# STM32F412Zx register map
File version: 1.0
Registers are 32-bit, read-write, reset 0x0 unless marked. A register's access mark holds for its fields unless they carry their own. Offsets are from the block's base; [hi:lo] are bit positions; {n}, {i} and the like mark numbered series; 'fields as' and 'values as' point back to an identical list.

## SYSCFG — System configuration controller
Base 0x40013800
0x00 MEMRMP — SYSCFG memory remap register
  [1:0] MEM_MODE — SYSCFG_Memory Remap Config
    0=FLASH (Main Flash memory mapped at 0x00000000); 1=SYSTEMFLASH (System Flash memory mapped at 0x00000000); 3=SRAM (SRAM1 mapped at 0x00000000); 2=FSMC (FSMC(NOR/PSRAM 1 and 2) mapped at 0x00000000)
0x04 PMC — SYSCFG peripheral mode configuration register
  [16] ADC1DC2 — Refer to AN4073 on how to use this bit
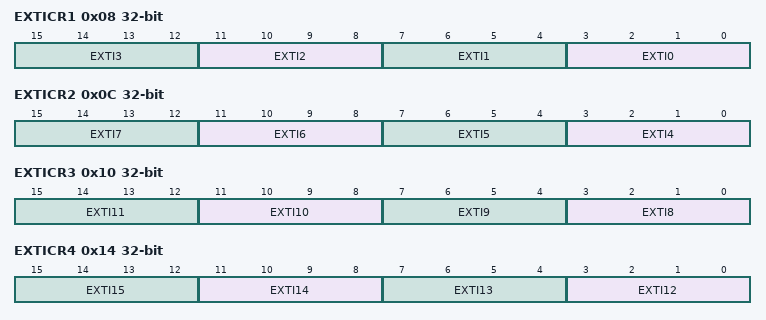
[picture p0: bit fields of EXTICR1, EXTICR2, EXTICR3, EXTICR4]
0x08 EXTICR1 — SYSCFG external interrupt configuration registers
  [4n+3:4n] EXTI{n} (n=0..3) — EXTI {n} configuration
0x0C EXTICR2 — SYSCFG external interrupt configuration registers
  [4n-13:4n-16] EXTI{n} (n=4..7) — EXTI {n} configuration
0x10 EXTICR3 — SYSCFG external interrupt configuration registers
  [4n-29:4n-32] EXTI{n} (n=8..11) — EXTI {n} configuration
0x14 EXTICR4 — SYSCFG external interrupt configuration registers
  [4n-45:4n-48] EXTI{n} (n=12..15) — EXTI {n} configuration
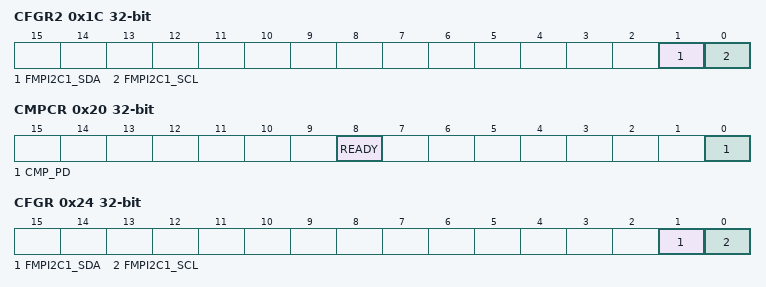
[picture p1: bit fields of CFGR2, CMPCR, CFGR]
0x1C CFGR2 — SYSCFG Configuration register2
  [1] FMPI2C1_SDA — FM+ drive capability for FMPI2C1_SDA pin
  [0] FMPI2C1_SCL — FM+ drive capability for FMPI2C1_SCL pin
0x20 CMPCR — SYSCFG Compensation cell control register
  [8] READY — Compensation cell power-down
  [0] CMP_PD — Compensation cell ready flag
0x24 CFGR — SYSCFG Configuration register
  fields as CFGR2

## EXTI — External Interrupt/Event Controller
Base 0x40013C00
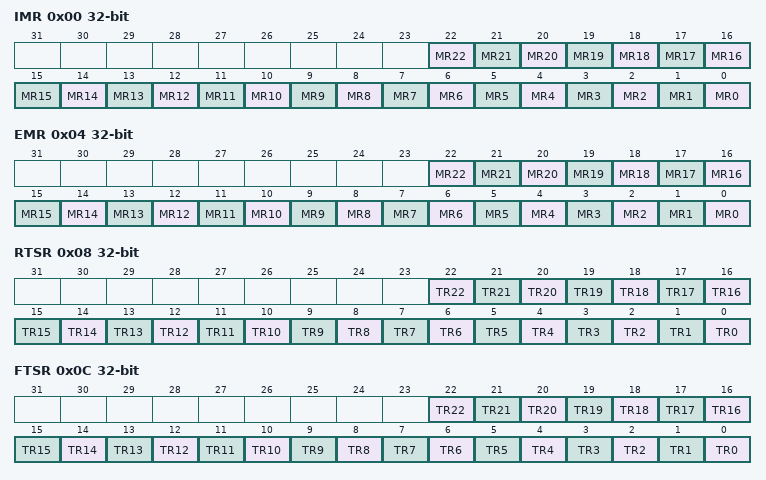
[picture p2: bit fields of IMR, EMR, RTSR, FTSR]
0x00 IMR — EXTI Interrupt mask register
  [n] MR{n} (n=0..22) — Interrupt Mask on line {n}
0x04 EMR — EXTI Event mask register
  [n] MR{n} (n=0..22) — Event Mask on line {n}
0x08 RTSR — EXTI Rising trigger selection register
  [n] TR{n} (n=0..22) — Rising trigger event configuration bit of line {n}
0x0C FTSR — EXTI Falling trigger selection register
  [n] TR{n} (n=0..22) — Falling trigger event configuration bit of line {n}
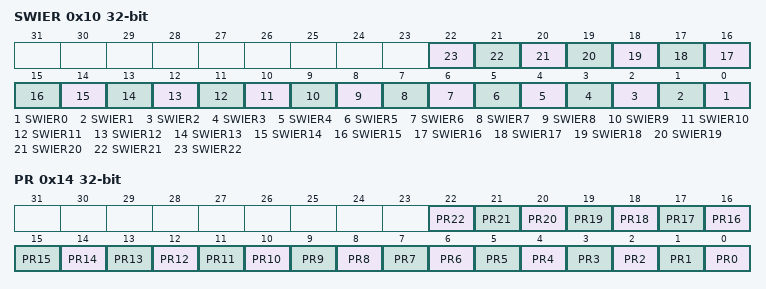
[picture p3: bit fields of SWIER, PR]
0x10 SWIER — EXTI Software interrupt event register
  [n] SWIER{n} (n=0..22) — Software Interrupt on line {n}
0x14 PR — EXTI Pending register
  [n] PR{n} (n=0..22) — Pending bit for line {n}

## GPIOA — General Purpose I/O
Base 0x40020000
Same registers: GPIOB 0x40020400, GPIOC 0x40020800, GPIOD 0x40020C00, GPIOE 0x40021000, GPIOF 0x40021400, GPIOG 0x40021800, GPIOH 0x40021C00
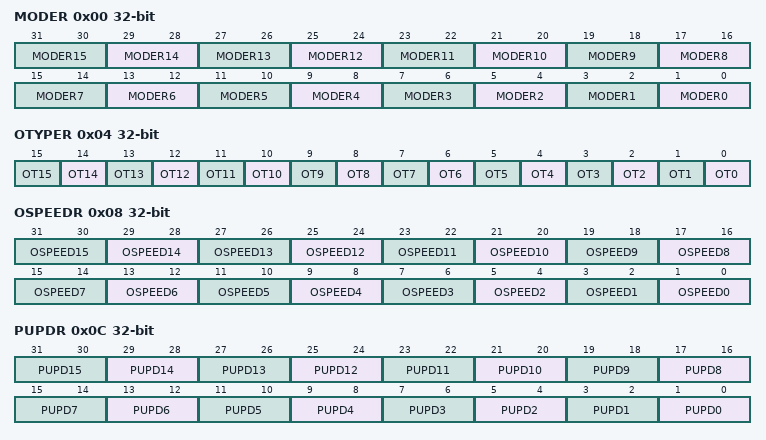
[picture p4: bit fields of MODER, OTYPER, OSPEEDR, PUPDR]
0x00 MODER — GPIO port mode register
  [2n+1:2n] MODER{n} (n=0..15)
0x04 OTYPER — GPIO port output type register
  [n] OT{n} (n=0..15)
0x08 OSPEEDR — GPIO port output speed register
  [2n+1:2n] OSPEED{n} (n=0..15)
0x0C PUPDR — GPIO port pull-up/pull-down register
  [2n+1:2n] PUPD{n} (n=0..15)
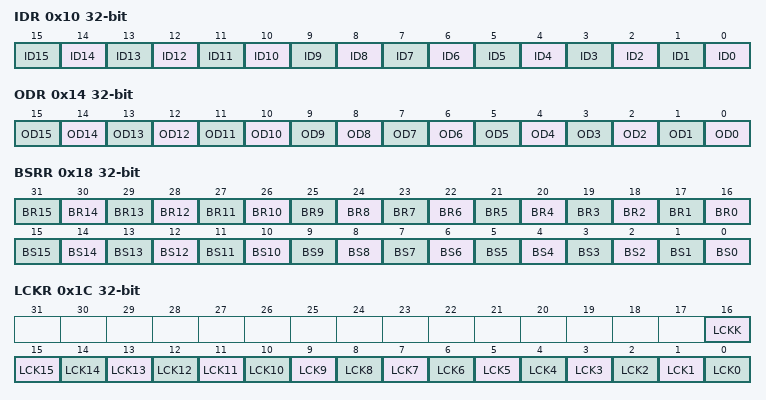
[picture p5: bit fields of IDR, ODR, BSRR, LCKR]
0x10 IDR — GPIO port input data register
  [n] ID{n} (n=0..15)
0x14 ODR — GPIO port output data register
  [n] OD{n} (n=0..15)
0x18 BSRR — GPIO port bit set/reset register
  [n+16] BR{n} (n=0..15), [n] BS{n} (n=0..15)
0x1C LCKR — GPIO port configuration lock register
  [16] LCKK, [n] LCK{n} (n=0..15)
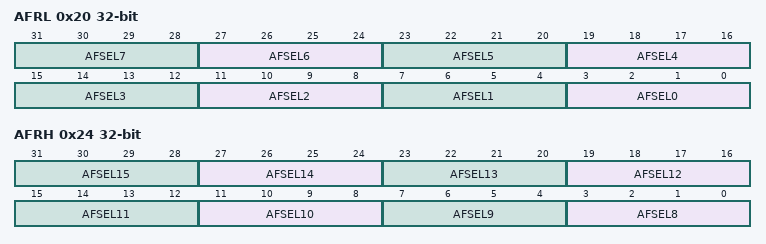
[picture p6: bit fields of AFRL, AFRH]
0x20 AFRL — GPIO alternate function registers
  [4n+3:4n] AFSEL{n} (n=0..7)
0x24 AFRH — GPIO alternate function registers
  [4n-29:4n-32] AFSEL{n} (n=8..15)

## CRC — CRC calculation unit
Base 0x40023000
0x00 DR — CRC Data register
  [31:0] DR — Data register bits
0x04 IDR 8-bit — CRC Independent data register
  [7:0] IDR — General-purpose 8-bit data register bits
0x08 CR — CRC Control register
  [0] RESET — RESET bit

## FLASH — FLASH Registers
Base 0x40023C00
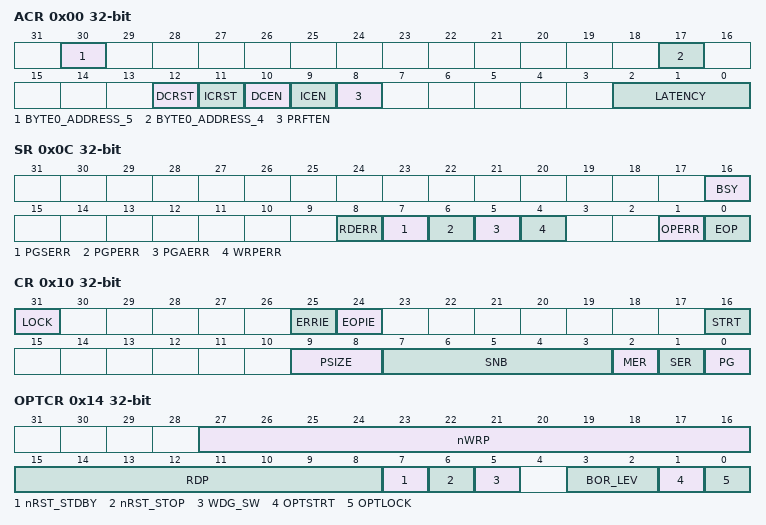
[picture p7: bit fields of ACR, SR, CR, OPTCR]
0x00 ACR — FLASH access control register
  [30] BYTE0_ADDRESS_5
  [17] BYTE0_ADDRESS_4
  [12] DCRST
  [11] ICRST
  [10] DCEN
  [9] ICEN
  [8] PRFTEN
  [2:0] LATENCY
    0=FLASH Zero wait state; 1=FLASH One wait state; 2=FLASH Two wait states; 3=FLASH Three wait states; 4=FLASH Four wait states; 5=FLASH five wait state; 6=FLASH six wait state; 7=FLASH seven wait states
0x04 KEYR — FLASH key register
0x08 OPTKEYR — FLASH option key register
0x0C SR — FLASH status register
  [16] BSY, [8] RDERR, [7] PGSERR, [6] PGPERR, [5] PGAERR, [4] WRPERR, [1] OPERR, [0] EOP
0x10 CR — FLASH control register
  [31] LOCK, [25] ERRIE, [24] EOPIE, [16] STRT, [9:8] PSIZE, [7:3] SNB, [2] MER, [1] SER, [0] PG
0x14 OPTCR — FLASH option control register
  [27:16] nWRP, [15:8] RDP, [7] nRST_STDBY, [6] nRST_STOP, [5] WDG_SW, [3:2] BOR_LEV, [1] OPTSTRT, [0] OPTLOCK
0x18 OPTCR1 — FLASH option control register 1
  [27:16] nWRP
